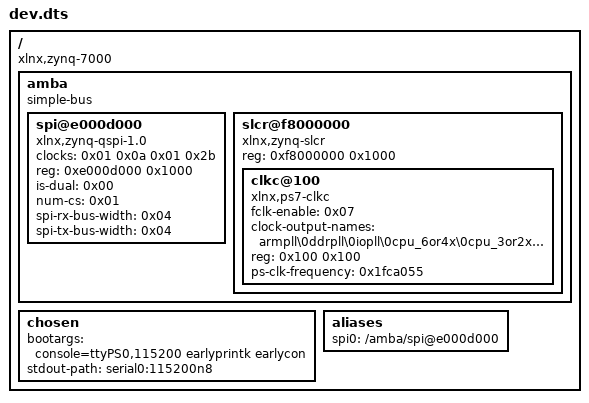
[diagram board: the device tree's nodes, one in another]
/dts-v1/;

/ {
	#address-cells = <0x01>;
	#size-cells = <0x01>;
	compatible = "xlnx,zynq-7000";

	amba {
		compatible = "simple-bus";
		#address-cells = <0x01>;
		#size-cells = <0x01>;
		ranges;

		spi@e000d000 {
			clock-names = "ref_clk\0pclk";
			clocks = <0x01 0x0a 0x01 0x2b>;
			compatible = "xlnx,zynq-qspi-1.0";
			status = "okay";
			reg = <0xe000d000 0x1000>;
			#address-cells = <0x01>;
			#size-cells = <0x00>;
			is-dual = <0x00>;
			num-cs = <0x01>;
			spi-rx-bus-width = <0x04>;
			spi-tx-bus-width = <0x04>;
		};

		slcr@f8000000 {
			#address-cells = <0x01>;
			#size-cells = <0x01>;
			compatible = "xlnx,zynq-slcr\0syscon\0simple-mfd";
			reg = <0xf8000000 0x1000>;
			ranges;
			phandle = <0x09>;

			clkc@100 {
				#clock-cells = <0x01>;
				compatible = "xlnx,ps7-clkc";
				fclk-enable = <0x07>;
				clock-output-names = "armpll\0ddrpll\0iopll\0cpu_6or4x\0cpu_3or2x\0cpu_2x\0cpu_1x\0ddr2x\0ddr3x\0dci\0lqspi\0smc\0pcap\0gem0\0gem1\0fclk0\0fclk1\0fclk2\0fclk3\0can0\0can1\0sdio0\0sdio1\0uart0\0uart1\0spi0\0spi1\0dma\0usb0_aper\0usb1_aper\0gem0_aper\0gem1_aper\0sdio0_aper\0sdio1_aper\0spi0_aper\0spi1_aper\0can0_aper\0can1_aper\0i2c0_aper\0i2c1_aper\0uart0_aper\0uart1_aper\0gpio_aper\0lqspi_aper\0smc_aper\0swdt\0dbg_trc\0dbg_apb";
				reg = <0x100 0x100>;
				ps-clk-frequency = <0x1fca055>;
				phandle = <0x01>;
			};
		};
	};

	chosen {
		bootargs = "console=ttyPS0,115200 earlyprintk earlycon";
		stdout-path = "serial0:115200n8";
	};

	aliases {
		spi0 = "/amba/spi@e000d000";
	};
};
